# WDTIMER2 register map
Vendor: Texas Instruments
Peripheral module from a debugger description file (folder omap34xx).
Registers are 32-bit, access per field, reset 0x0 unless marked. A register's access mark holds for its fields unless they carry their own. Offsets are as the file gives them; lines under a group give offsets from that group; [hi:lo] are bit positions; {n}, {i} and the like mark numbered series; 'fields as' and 'values as' point back to an identical list; <NAME> marks a mode.

## WDTIMER2
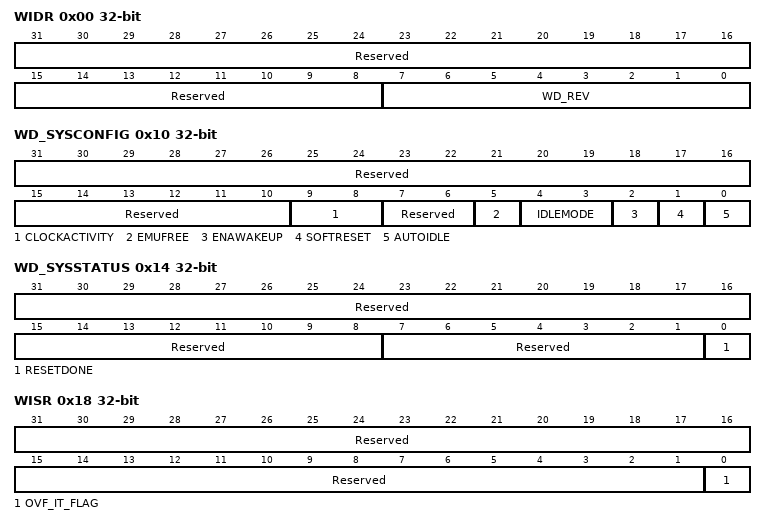
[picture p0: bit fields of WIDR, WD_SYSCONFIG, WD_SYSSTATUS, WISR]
0x00 WIDR ro (reset mask 0xFFFFFF00) — This register contains the IP revision code.
  [31:8] Reserved — Reads return 0.
  [7:0] WD_REV — IP revision[7:4] . Major revision . [3:0] . Minor revision . Examples: 0x10 for 1.0, 0x21 for 2.1 .
0x10 WD_SYSCONFIG — This register controls the various parameters of the L4 interface.
  [31:10] Reserved ro — Write 0s for future compatibility. Reads return 0.
  [9:8] CLOCKACTIVITY rw — Clock Activity selection bits.
    0=Both clocks can be cut off; 1=Only L4 clock must be kept active; timer clock can be cut off; 2=Only timer clock must be kept active; L4 clock can be cut off; 3=both clocks must be kept active
  [7:6] Reserved ro — Write 0s for future compatibility. Reads return 0.
  [5] EMUFREE rw — Emulation mode
    0=Timer counter frozen in emulation; 1=Timer counter free-running in emulation
  [4:3] IDLEMODE rw — Idle mode selection bits
    0=Force Idle mode; 1=No Idle mode; 2=Smart Idle mode
  [2] ENAWAKEUP rw — Enable wakeup control bit
    0=Wakeup mechanism is disabled; 1=Wakeup mechanism is enabled
  [1] SOFTRESET rw — Software reset. This bit is automatically reset by the hardware. During reads, it always return 0.
    0=Normal mode; 1=The module is reset
  [0] AUTOIDLE rw — L4 interconnect clock gating strategy
    0=L4 interface clock is free-running; 1=Automatic L4 interface clock gating strategy is applied, based on the L4 interface activity
0x14 WD_SYSSTATUS ro (reset mask 0xFFFFFFFE) — This register provides status information about the module, excluding the interrupt status information.
  [31:8] Reserved — Reads return 0.
  [7:1] Reserved — Reads return 0.
  [0] RESETDONE — Internal reset monitoring
    0=Internal module reset in ongoing; 1=Reset completed
0x18 WISR — This register shows which interrupt events are pending inside the module.
  [31:1] Reserved ro — Reads return 0.
  [0] OVF_IT_FLAG rw — Pending overflow interrupt status
    0=OVF_IT_FLAG_0_r (No overflow interrupt pending); 0=OVF_IT_FLAG_0_w (Status unchanged); 1=OVF_IT_FLAG_1_r (Overflow interrupt pending); 1=OVF_IT_FLAG_1_w (Status bit cleared)
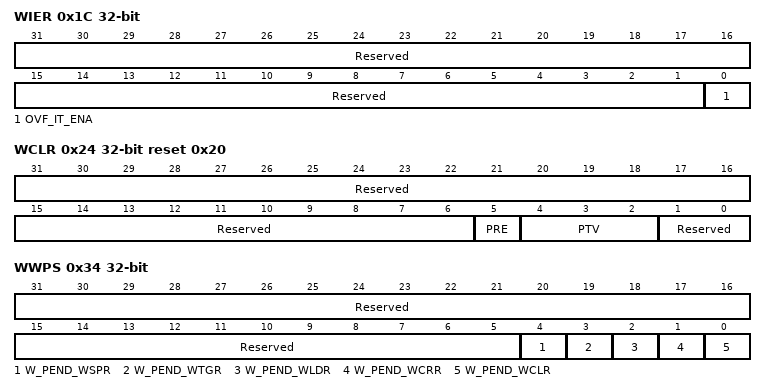
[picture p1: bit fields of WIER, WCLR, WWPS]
0x1C WIER — This register shows controls (enable/disable) the interrupt events.
  [31:1] Reserved ro — Reads return 0.
  [0] OVF_IT_ENA rw — Enable overflow interrupt
    0=Disable overflow interrupt; 1=Enable overflow interrupt
0x24 WCLR reset 0x20 — This register controls the prescaler stage of the counter.
  [31:6] Reserved ro — Reads return 0.
  [5] PRE rw — Prescaler enable
    0=Prescaler disabled; 1=Prescaler enabled
  [4:2] PTV rw — Prescaler value: The timer counter is prescaled with the value: pow(2,PTV) Example: PTV = 2: counter increases value is started after 4 functional clock periods.
  [1:0] Reserved ro — Reads return 0.
0x28 WCRR rw — This register holds the value of the internal counter.
  [31:0] TIMER_COUNTER — The value of the timer counter register
0x2C WLDR rw reset not defined — This register holds the timer load value.
  [31:0] TIMER_LOAD — The value of the timer load register
0x30 WTGR rw — Writing a different value than the one already written in this register causes a watchdog counter reload.
  [31:0] TTGR_VALUE — The value of the trigger register
0x34 WWPS ro — This register contains the write posting bits for all write-able functional registers.
  [31:5] Reserved — Reads return 0
  [4] W_PEND_WSPR — Write pending for registerWSPR 0x0: No Start-Stop Register write pending0x1: Start-Stop Register write pending
  [3] W_PEND_WTGR — Write pending for registerWTGR 0x0: No Trigger Register write pending0x1: Trigger Register write pending
  [2] W_PEND_WLDR — Write pending for registerWLDR 0x0: No Load Register write pending0x1: Load Register write pending
  [1] W_PEND_WCRR — Write pending for registerWCRR 0x0: No Counter Register write pending0x1: Counter Register write pending
  [0] W_PEND_WCLR — Write pending for registerWCLR 0x0: No Control Register write pending0x1: Control Register write pending
0x48 WSPR rw — This register holds the start-stop value that controls the internal start-stop FSM.
  [31:0] WSPR_VALUE — The value of the start/stop register
